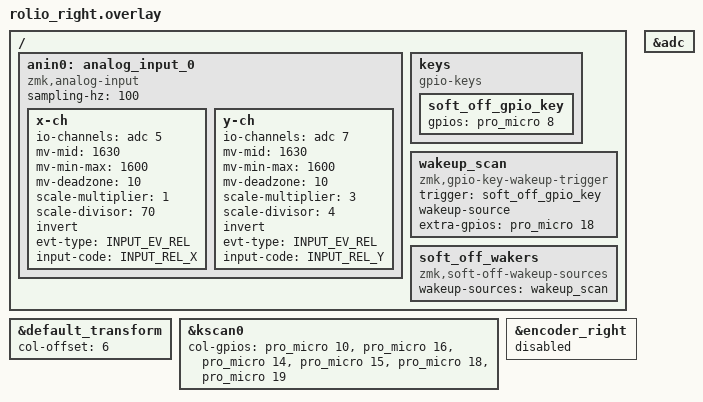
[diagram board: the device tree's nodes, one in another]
#include "rolio.dtsi"
#include <zephyr/dt-bindings/input/input-event-codes.h>

&default_transform {
    col-offset = <6>;
};

&kscan0 {
    col-gpios
        = <&pro_micro 10 GPIO_ACTIVE_HIGH>
        , <&pro_micro 16 GPIO_ACTIVE_HIGH>
        , <&pro_micro 14 GPIO_ACTIVE_HIGH>
        , <&pro_micro 15 GPIO_ACTIVE_HIGH>
        , <&pro_micro 18 GPIO_ACTIVE_HIGH>
        , <&pro_micro 19 GPIO_ACTIVE_HIGH>
        ;
};

&encoder_right {
    status = "disabled";
};

&adc {
    status = "okay";
};

/ {
    anin0: analog_input_0 {
        compatible = "zmk,analog-input";
        sampling-hz = <100>;
        x-ch {
            io-channels = <&adc 5>;
            mv-mid = <1630>;
            mv-min-max = <1600>;
            mv-deadzone = <10>;
            scale-multiplier = <1>;
            scale-divisor = <70>;
            invert;
            evt-type = <INPUT_EV_REL>;
            input-code = <INPUT_REL_X>;
        };
        y-ch {
            io-channels = <&adc 7>;
            mv-mid = <1630>;
            mv-min-max = <1600>;
            mv-deadzone = <10>;
            scale-multiplier = <3>;
            scale-divisor = <4>;
            invert;
            evt-type = <INPUT_EV_REL>;
            input-code = <INPUT_REL_Y>;
        };
    };
};


/ {
    keys {
        compatible = "gpio-keys";
        soft_off_gpio_key: soft_off_gpio_key {
            gpios = <&pro_micro 8 (GPIO_ACTIVE_HIGH | GPIO_PULL_DOWN)>;
        };
    };
};

/ {
    wakeup_scan: wakeup_scan {
        compatible = "zmk,gpio-key-wakeup-trigger";
        trigger = <&soft_off_gpio_key>;
        wakeup-source;
        extra-gpios = <&pro_micro 18 GPIO_ACTIVE_HIGH>;
    };
};

/ {
    soft_off_wakers {
        compatible = "zmk,soft-off-wakeup-sources";
        wakeup-sources = <&wakeup_scan>;
    };
};
